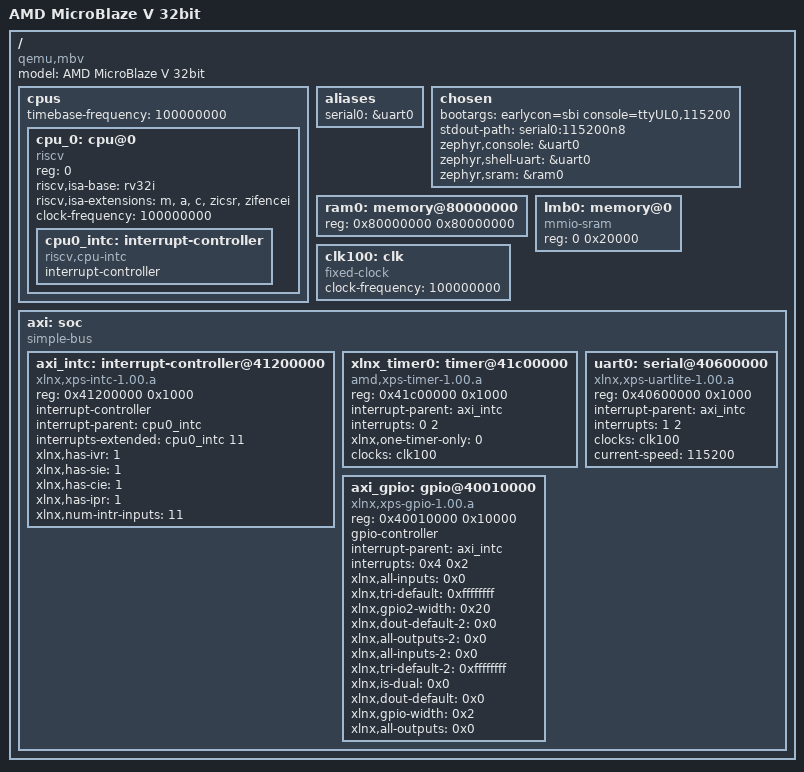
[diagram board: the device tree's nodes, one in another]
/*
 * Copyright (c) 2026, Advanced Micro Devices, Inc.
 *
 * SPDX-License-Identifier: Apache-2.0
 */

/dts-v1/;

/ {
	#address-cells = <1>;
	#size-cells = <1>;
	model = "AMD MicroBlaze V 32bit";
	compatible = "qemu,mbv", "amd,mbv";

	cpus: cpus {
		#address-cells = <1>;
		#size-cells = <0>;
		timebase-frequency = <100000000>;

		cpu_0: cpu@0 {
			compatible = "riscv";
			device_type = "cpu";
			reg = <0>;
			riscv,isa-base = "rv32i";
			riscv,isa-extensions = "m", "a", "c", "zicsr", "zifencei";
			clock-frequency = <100000000>;

			cpu0_intc: interrupt-controller {
				compatible = "riscv,cpu-intc";
				interrupt-controller;
				#interrupt-cells = <1>;
			};
		};
	};

	aliases {
		serial0 = &uart0;
	};

	chosen {
		bootargs = "earlycon=sbi console=ttyUL0,115200";
		stdout-path = "serial0:115200n8";
		zephyr,console = &uart0;
		zephyr,shell-uart = &uart0;
		zephyr,sram = &ram0;
	};

	ram0: memory@80000000 {
		device_type = "memory";
		reg = <0x80000000 0x80000000>;
	};

	lmb0: memory@0 {
		compatible = "mmio-sram";
		reg = <0 0x20000>;
	};

	clk100: clk {
		compatible = "fixed-clock";
		#clock-cells = <0>;
		clock-frequency = <100000000>;
	};

	axi: soc {
		#address-cells = <1>;
		#size-cells = <1>;
		compatible = "simple-bus";
		ranges;
		bootph-all;

		axi_intc: interrupt-controller@41200000 {
			compatible = "xlnx,xps-intc-1.00.a";
			reg = <0x41200000 0x1000>;
			interrupt-controller;
			interrupt-parent = <&cpu0_intc>;
			#interrupt-cells = <2>;
			interrupts-extended = <&cpu0_intc 11>;
			xlnx,has-ivr = <1>;
			xlnx,has-sie = <1>;
			xlnx,has-cie = <1>;
			xlnx,has-ipr = <1>;
			xlnx,num-intr-inputs = <11>;
		};

		xlnx_timer0: timer@41c00000 {
			compatible = "amd,xps-timer-1.00.a";
			reg = <0x41c00000 0x1000>;
			interrupt-parent = <&axi_intc>;
			interrupts = <0 2>;
			xlnx,one-timer-only = <0>;
			clocks = <&clk100>;
		};

		uart0: serial@40600000 {
			compatible = "xlnx,xps-uartlite-1.00.a";
			reg = <0x40600000 0x1000>;
			interrupt-parent = <&axi_intc>;
			interrupts = <1 2>;
			clocks = <&clk100>;
			current-speed = <115200>;
		};

		axi_gpio: gpio@40010000 {
			compatible = "xlnx,xps-gpio-1.00.a";
			reg = <0x40010000 0x10000>;
			gpio-controller;
			interrupt-parent = <&axi_intc>;
			interrupts = <0x4 0x2>;
			#gpio-cells = <0x2>;
			xlnx,all-inputs = <0x0>;
			xlnx,tri-default = <0xffffffff>;
			xlnx,gpio2-width = <0x20>;
			xlnx,dout-default-2 = <0x0>;
			xlnx,all-outputs-2 = <0x0>;
			xlnx,all-inputs-2 = <0x0>;
			xlnx,tri-default-2 = <0xffffffff>;
			xlnx,is-dual = <0x0>;
			xlnx,dout-default = <0x0>;
			xlnx,gpio-width = <0x2>;
			xlnx,all-outputs = <0x0>;
		};
	};
};
